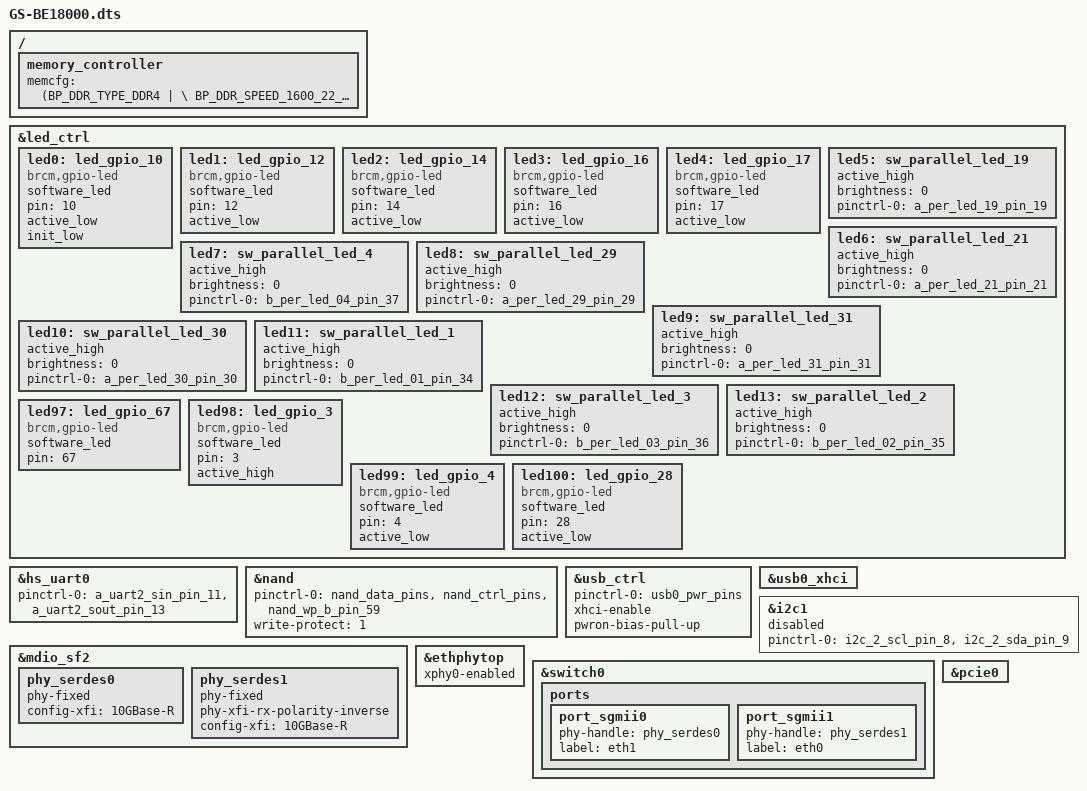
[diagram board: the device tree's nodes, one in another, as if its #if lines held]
#include "6766.dtsi"

/ {
    memory_controller {
        memcfg = <(BP_DDR_TYPE_DDR4       | \
            BP_DDR_SPEED_1600_22_22_22    | \
            BP_DDR_TOTAL_SIZE_2048MB      | \
            BP_DDR_DEVICE_WIDTH_16        | \
            BP_DDR_TOTAL_WIDTH_16BIT      | \
            BP_DDR_TEMP_EXTENDED_ASR      | \
            BP_DDR_6766_DEFAULT           | \
            BP_DDR_CONFIG_DEBUG)>;
    };

/* remove mark if need
	buttons {
        compatible = "brcm,buttons";

        reset_button {
            ext_irq = <&bca_extintr 6 GPIO_ACTIVE_LOW (BCA_EXTINTR_TYPE_LOW_LEVEL | BCA_EXTINTR_TYPE_SENSE_EDGE)>;
            press {
                print = "Button Press -- Hold for 5s to do restore to default";
            };
            hold {
                rst_to_dflt = <5>;
            };
            release {
                reset = <0>;
            };
        };

        ses_button {
            ext_irq = <&bca_extintr 18 GPIO_ACTIVE_LOW (BCA_EXTINTR_TYPE_LOW_LEVEL | BCA_EXTINTR_TYPE_SENSE_EDGE)>;
            release {
                ses_short_period = <0>;
                ses_long_period = <3>;
            };
        };
	};
*/
};

&led_ctrl {
    /* Power_LED: GPIO LED */
    led0: led_gpio_10 {
	compatible = "brcm,gpio-led";
	software_led;
	pin = <10>;
	active_low;
	init_low;
    };
    /* WAN_LED */
    led1: led_gpio_12 {
	compatible = "brcm,gpio-led";
	software_led;
	pin = <12>;
        active_low;
    };
    /* LAN_LED */
    led2: led_gpio_14 {
	compatible = "brcm,gpio-led";
	software_led;
	pin = <14>;
        active_low;
    };
    /* WAN_RED_LED */
    led3: led_gpio_16 {
	compatible = "brcm,gpio-led";
	software_led;
	pin = <16>;
	active_low;
    };
    /* WLAN_LED */
    led4: led_gpio_17 {
	compatible = "brcm,gpio-led";
        software_led;
	pin = <17>;
        active_low;
    };

    /* LED_RED */
    led5: sw_parallel_led_19 {
        active_high;
        brightness = <0>;
        pinctrl-0 = <&a_per_led_19_pin_19>;
        status = "okay";
    };
    /* LED_GREEN */
    led6: sw_parallel_led_21 {
        active_high;
        brightness = <0>;
        pinctrl-0 = <&a_per_led_21_pin_21>;
        status = "okay";
    };
    /* LED_BLUE */
    led7: sw_parallel_led_4 {
        active_high;
        brightness = <0>;
        pinctrl-0 = <&b_per_led_04_pin_37>;
        status = "okay";
    };

    /* LED_RED */
    led8: sw_parallel_led_29 {
        active_high;
        brightness = <0>;
        pinctrl-0 = <&a_per_led_29_pin_29>;
        status = "okay";
    };
    /* LED_GREEN */
    led9: sw_parallel_led_31 {
        active_high;
        brightness = <0>;
        pinctrl-0 = <&a_per_led_31_pin_31>;
        status = "okay";
    };
    /* LED_BLUE */
    led10: sw_parallel_led_30 {
        active_high;
        brightness = <0>;
        pinctrl-0 = <&a_per_led_30_pin_30>;
        status = "okay";
    };
    
    /* LED_RED */
    led11: sw_parallel_led_1 {
        active_high;
        brightness = <0>;
        pinctrl-0 = <&b_per_led_01_pin_34>;
        status = "okay";
    };
    /* LED_GREEN */
    led12: sw_parallel_led_3 {
        active_high;
        brightness = <0>;
        pinctrl-0 = <&b_per_led_03_pin_36>;
        status = "okay";
    };
    /* LED_BLUE */
    led13: sw_parallel_led_2 {
        active_high;
        brightness = <0>;
        pinctrl-0 = <&b_per_led_02_pin_35>;
        status = "okay";
    };

	/* USB Power */
	led97:led_gpio_67 {
		compatible = "brcm,gpio-led";
		software_led;
		pin = <67>;
	};
        /* CC3220R reset */
        led98: led_gpio_3 {
                compatible = "brcm,gpio-led";
                software_led;
                pin = <3>;
                active_high;
        };
        /* CC3220R GPIO 7 */
        led99: led_gpio_4 {
                compatible = "brcm,gpio-led";
                software_led;
                pin = <4>;
                active_low;
        };
	/* MxL86282C reset */
	led100: led_gpio_28 {
		compatible = "brcm,gpio-led";
		software_led;
		pin = <28>;
		active_low;
	};
};

/* For CC3220R */
&hs_uart0 {
    pinctrl-0 = <&a_uart2_sin_pin_11 &a_uart2_sout_pin_13>;
    pinctrl-names = "default";
    status = "okay";
};

&nand {
    pinctrl-0 = <&nand_data_pins &nand_ctrl_pins &nand_wp_b_pin_59>;
    write-protect = <1>;
    status = "okay";
};

&usb_ctrl {
    pinctrl-names="default";
    pinctrl-0 = <&usb0_pwr_pins>;
    status = "okay";
    xhci-enable;
    pwron-bias-pull-up;
};
&usb0_xhci {
    status = "okay";
};

&i2c1 {
    pinctrl-names = "default";
    pinctrl-0 = <&i2c_2_scl_pin_8 &i2c_2_sda_pin_9>;
    status = "disabled";
};

&mdio_sf2 {
    /* Port PHY mapping:
	        port_imp -8#0- port_gphy <----> phy_gphy
                      # 5- port_sgmii0 <--> phy_serdes0 - phy_cascade0 -- MxL86282C SGMII1
                      # 6- port_sgmii1 <--> phy_serdes1 - phy_cascade1 -- MxL86282C SGMII0
     */
/*
	phy_gphy {
*/
        /* MxL86252C reset pin, pull up by default(RM77). Remove this remark if need.
           phy-reset = <&gpioc 28 GPIO_ACTIVE_HIGH>;
         */
/*
        status = "okay";
    };
*/
    /* Enable SerDes0 for MxL86282C USXGMII-1  */
    phy_serdes0 {
        phy-fixed;
        config-xfi = "10GBase-R";
        status = "okay";
    };

    /* Enable SerDes1 for MxL86282C USXGMII-0  */
    phy_serdes1 {
        phy-fixed;
        phy-xfi-rx-polarity-inverse;
        config-xfi = "10GBase-R";
        status = "okay";
    };
};

&ethphytop {
    xphy0-enabled;
    status = "okay";
};

&switch0 {
    ports {
/*
        port_gphy {
            phy-handle = <&phy_gphy>;
            status = "okay";
            label = "eth2";
        };
*/
        port_sgmii0 {
            phy-handle = <&phy_serdes0>;
            status = "okay";
            label = "eth1";
        };

        port_sgmii1 {
            phy-handle = <&phy_serdes1>;
            status = "okay";
            label = "eth0";
        };
    };
};

#if defined(CONFIG_BCM_PCIE_HCD) || defined(CONFIG_BCM_PCIE_HCD_MODULE)
/**********************************************************************/
/* GPIO: Add one define per GPIO (individual or shared) regulator     */
/*       - Skip if no GPIO regulators in use                          */
/**********************************************************************/
#define PCIE0_REG_GPIO    15    /* PCIE0_PWR_CTRL for vreg_pcie0 node */

#include "../bcm_wlan_regulator.dtsi"

/**********************************************************************/
/* Shared: Add brcm,supply-names = "vreg-pcieX" for shared PCIe nodes */
/*         - Skip if not using shared GPIO regulators                 */
/**********************************************************************/

/**********************************************************************/
/* PCIe: Add status = "okay" for each PCIe slots of this boiard       */
/*       - Skip if this is a derivative board (already done in base)  */
/**********************************************************************/
&pcie0 {
	status = "okay";
};
#endif //#if defined(CONFIG_BCM_PCIE_HCD) || defined(CONFIG_BCM_PCIE_HCD_MODULE)
